VERSION ""

NS_ :

BS_:

BU_: OffBoardDiagnosticTool1 Modine_BTMS
VAL_TABLE_ FE 255 "Not Used" 254 "Unavailable" ;
VAL_TABLE_ FEFF 65535 "Not Used" 65279 "Unavailable" ;
VAL_TABLE_ exv_state_machine 3 "Complete" 2 "In Process" 1 "Start Request" 0 "Idle" ;
VAL_TABLE_ Manual_off_16 65535 "Manual mode disabled" ;
VAL_TABLE_ Manual_off_8 255 "Manual mode disabled" ;
VAL_TABLE_ cond_pressure_override 1 "On - set to 1450 kPa-g" 0 "Off - Auto pressure SP" ;
VAL_TABLE_ Pressure_switch 3 "Invalid" 1 "Closed (OK)" 0 "Open (fault)" ;
VAL_TABLE_ Digital_in 3 "Invalid" 1 "High (24V)" 0 "Low (0V)" ;

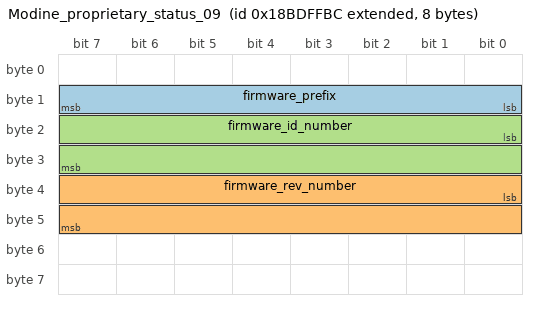
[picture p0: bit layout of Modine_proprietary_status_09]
BO_ 2562588604 Modine_proprietary_status_09: 8 Modine_BTMS
 SG_ firmware_prefix : 8|8@1+ (1,0) [0|255] "<none>" Vector__XXX
 SG_ firmware_rev_number : 32|16@1+ (1,0) [0|65535] "" Vector__XXX
 SG_ firmware_id_number : 16|16@1+ (1,0) [0|65535] "" Vector__XXX

CM_ SG_ 2562588604 firmware_rev_number "This is the second number in our firmware file name. For example, if the firmware file is 40BF00220033, this signal would return 33.";
CM_ SG_ 2562588604 firmware_id_number "This is the first number in our firmware file name. For example, if the firmware file is 40BF00220033, this signal would return 22.";
BA_DEF_ SG_  "J1939SLOT" STRING ;
BA_DEF_  "BaudRate" STRING ;
BA_DEF_  "DatabaseVersionDate" STRING ;
BA_DEF_  "DatabaseVersion" STRING ;
BA_DEF_ SG_  "SigType" ENUM  "Default","Range","RangeSigned","ASCII","Discrete","Control","ReferencePGN","DTC","StringDelimiter","StringLength","StringLengthControl","MessageCounter","MessageChecksum";
BA_DEF_ SG_  "GenSigEVName" STRING ;
BA_DEF_ SG_  "GenSigILSupport" ENUM  "No","Yes";
BA_DEF_ SG_  "GenSigSendType" ENUM  "Cyclic","OnWrite","OnWriteWithRepetition","OnChange","OnChangeWithRepetition","IfActive","IfActiveWithRepetition","NoSigSendType";
BA_DEF_ BO_  "GenMsgILSupport" ENUM  "No","Yes";
BA_DEF_ BU_  "NmStationAddress" INT 0 255;
BA_DEF_ BO_  "GenMsgSendType" ENUM  "cyclic","NotUsed","IfActive","NotUsed","NotUsed","NotUsed","NotUsed","NotUsed","noMsgSendType";
BA_DEF_ BO_  "GenMsgRequestable" INT 0 1;
BA_DEF_  "DBName" STRING ;
BA_DEF_  "BusType" STRING ;
BA_DEF_  "ProtocolType" STRING ;
BA_DEF_ BO_  "VFrameFormat" ENUM  "StandardCAN","ExtendedCAN","reserved","J1939PG";
BA_DEF_DEF_  "J1939SLOT" "-";
BA_DEF_DEF_  "BaudRate" "500K";
BA_DEF_DEF_  "DatabaseVersionDate" "1-March-2022";
BA_DEF_DEF_  "DatabaseVersion" "";
BA_DEF_DEF_  "SigType" "Default";
BA_DEF_DEF_  "GenSigEVName" "Env@Nodename_@Signame";
BA_DEF_DEF_  "GenSigILSupport" "Yes";
BA_DEF_DEF_  "GenSigSendType" "NoSigSendType";
BA_DEF_DEF_  "GenMsgILSupport" "Yes";
BA_DEF_DEF_  "NmStationAddress" 254;
BA_DEF_DEF_  "GenMsgSendType" "noMsgSendType";
BA_DEF_DEF_  "GenMsgRequestable" 1;
BA_DEF_DEF_  "DBName" "";
BA_DEF_DEF_  "BusType" "CAN";
BA_DEF_DEF_  "ProtocolType" "J1939";
BA_DEF_DEF_  "VFrameFormat" "J1939PG";
BA_ "DatabaseVersionDate" "03-SEP-2026";
BA_ "DatabaseVersion" "1.0.0";
BA_ "DBName" "Modine_proprietary";
BA_ "NmStationAddress" BU_ OffBoardDiagnosticTool1 249;
BA_ "NmStationAddress" BU_ Modine_BTMS 188;
VAL_ 2562588604 firmware_prefix 50 "Reserved" 48 "Reserved" 47 "Reserved" 46 "Reserved" 45 "Reserved" 44 "Reserved" 43 "Reserved" 41 "Reserved" 40 "Reserved" 39 "Reserved" 38 "Reserved" 37 "Reserved" 36 "Reserved" 34 "Reserved" 33 "Reserved" 32 "Reserved" 31 "Reserved" 30 "Reserved" 29 "Reserved" 27 "Reserved" 26 "Reserved" 25 "40TB" 24 "40RB" 23 "40MF" 22 "40TC" 20 "40EF" 19 "Reserved" 18 "Reserved" 17 "Reserved" 16 "Reserved" 13 "Reserved" 11 "Reserved" 10 "Reserved" 49 "Reserved" 42 "Reserved" 35 "Reserved" 28 "Reserved" 21 "40BF" 15 "Reserved" 14 "Reserved" 12 "Reserved" 9 "Reserved" 8 "Reserved" 7 "Reserved" 255 "Invalid or Not Used" 6 "Reserved" 5 "Reserved" 4 "Reserved" 3 "30MF" 2 "30TC" 1 "30BF" 0 "30EF" ;
